# STM32F102 register map
File version: 1.1
CPU: CM3 r1p1, little endian, no MPU, no FPU, 4 interrupt priority bits
Registers are 32-bit, read-write, reset 0x0 unless marked. A register's access mark holds for its fields unless they carry their own. Offsets are from the block's base; [hi:lo] are bit positions; {n}, {i} and the like mark numbered series; 'fields as' and 'values as' point back to an identical list.

## PWR — Power control
Base 0x40007000
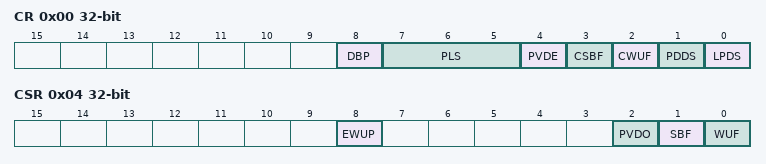
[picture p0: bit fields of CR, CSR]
0x00 CR — Power control register (PWR_CR)
  [8] DBP — Disable Backup Domain write protection
  [7:5] PLS — PVD Level Selection
  [4] PVDE — Power Voltage Detector Enable
  [3] CSBF — Clear STANDBY Flag
  [2] CWUF — Clear Wake-up Flag
  [1] PDDS — Power Down Deep Sleep
    0=STOP_MODE (Enter Stop mode when the CPU enters deepsleep); 1=STANDBY_MODE (Enter Standby mode when the CPU enters deepsleep)
  [0] LPDS — Low Power Deep Sleep
0x04 CSR access per field — Power control register (PWR_CR)
  [8] EWUP rw — Enable WKUP pin
  [2] PVDO ro — PVD Output
  [1] SBF ro — STANDBY Flag
  [0] WUF ro — Wake-Up Flag

## GPIOA — General purpose I/O
Base 0x40010800
Same registers: GPIOB 0x40010C00, GPIOC 0x40011000, GPIOD 0x40011400, GPIOE 0x40011800, GPIOF 0x40011C00, GPIOG 0x40012000
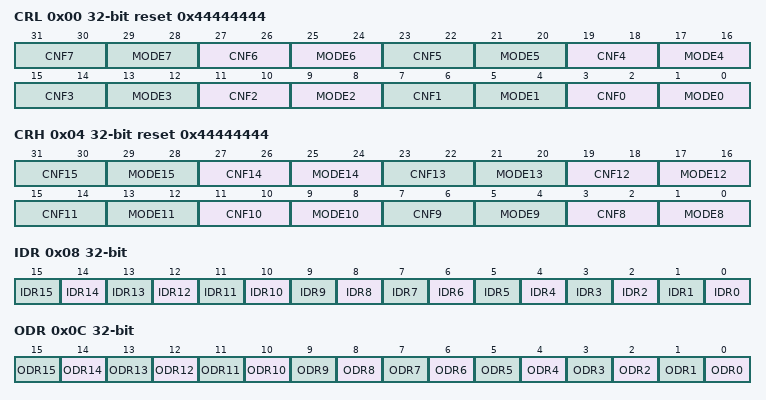
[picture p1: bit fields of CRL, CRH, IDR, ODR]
0x00 CRL reset 0x44444444 — Port configuration register low (GPIOn_CRL)
  [4n+3:4n+2] CNF{n} (n=0..7) — Port n.{n} configuration bits
    0=PushPull (Analog mode / Push-Pull mode); 1=OpenDrain (Floating input (reset state) / Open Drain-Mode); 2=AltPushPull (Input with pull-up/pull-down / Alternate Function Push-Pull Mode); 3=AltOpenDrain (Alternate Function Open-Drain Mode)
  [4n+1:4n] MODE{n} (n=0..7) — Port n.{n} mode bits
    0=Input mode (reset state); 1=Output mode 10 MHz; 2=Output2 (Output mode 2 MHz); 3=Output50 (Output mode 50 MHz)
0x04 CRH reset 0x44444444 — Port configuration register high (GPIOn_CRL)
  [4n-29:4n-30] CNF{n} (n=8..15) — Port n.{n} configuration bits
    values as CRL.CNF0
  [4n-31:4n-32] MODE{n} (n=8..15) — Port n.{n} mode bits
    values as CRL.MODE0
0x08 IDR ro — Port input data register (GPIOn_IDR)
  [n] IDR{n} (n=0..15) — Port input data
    0=Low (Input is logic low); 1=High (Input is logic high)
0x0C ODR — Port output data register (GPIOn_ODR)
  [n] ODR{n} (n=0..15) — Port output data
    0=Low (Set output to logic low); 1=High (Set output to logic high)
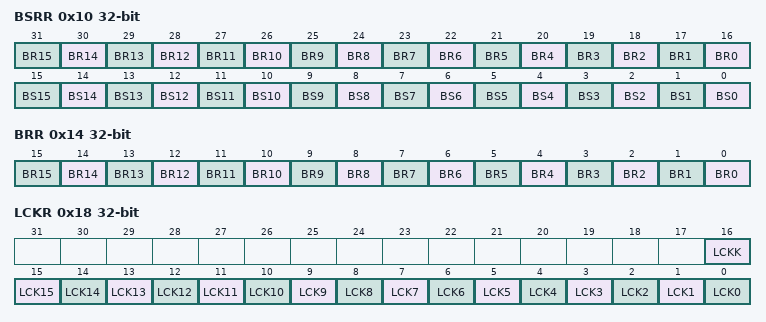
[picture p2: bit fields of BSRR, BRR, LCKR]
0x10 BSRR wo — Port bit set/reset register (GPIOn_BSRR)
  [n+16] BR{n} (n=0..15) — Reset bit {n}
    1=Resets the corresponding ODRx bit
  [n] BS{n} (n=0..15) — Set bit {n}
    1=Set (Sets the corresponding ODRx bit)
0x14 BRR wo — Port bit reset register (GPIOn_BRR)
  [n] BR{n} (n=0..15) — Reset bit {n}
    0=No action on the corresponding ODx bit; 1=Reset the ODx bit
0x18 LCKR — Port configuration lock register
  [16] LCKK — Lock key
    0=NotActive (Port configuration lock key not active); 1=Active (Port configuration lock key active)
  [n] LCK{n} (n=0..15) — Port A Lock bit {n}
    0=Unlocked (Port configuration not locked); 1=Locked (Port configuration locked)

## AFIO — Alternate function I/O
Base 0x40010000
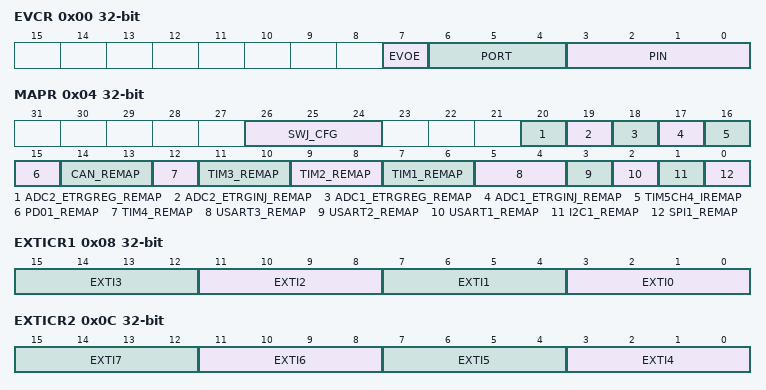
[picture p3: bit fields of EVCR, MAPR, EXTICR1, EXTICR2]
0x00 EVCR — Event Control Register (AFIO_EVCR)
  [7] EVOE — Event Output Enable
  [6:4] PORT — Port selection
  [3:0] PIN — Pin selection
0x04 MAPR access per field — AF remap and debug I/O configuration register (AFIO_MAPR)
  [26:24] SWJ_CFG wo — Serial wire JTAG configuration
  [20] ADC2_ETRGREG_REMAP rw — ADC 2 external trigger regular conversion remapping
  [19] ADC2_ETRGINJ_REMAP rw — ADC 2 external trigger injected conversion remapping
  [18] ADC1_ETRGREG_REMAP rw — ADC 1 external trigger regular conversion remapping
  [17] ADC1_ETRGINJ_REMAP rw — ADC 1 External trigger injected conversion remapping
  [16] TIM5CH4_IREMAP rw — Set and cleared by software
  [15] PD01_REMAP rw — Port D0/Port D1 mapping on OSCIN/OSCOUT
  [14:13] CAN_REMAP rw — CAN1 remapping
  [12] TIM4_REMAP rw — TIM4 remapping
  [11:10] TIM3_REMAP rw — TIM3 remapping
  [9:8] TIM2_REMAP rw — TIM2 remapping
  [7:6] TIM1_REMAP rw — TIM1 remapping
  [5:4] USART3_REMAP rw — USART3 remapping
  [3] USART2_REMAP rw — USART2 remapping
  [2] USART1_REMAP rw — USART1 remapping
  [1] I2C1_REMAP rw — I2C1 remapping
  [0] SPI1_REMAP rw — SPI1 remapping
0x08 EXTICR1 — External interrupt configuration register 1 (AFIO_EXTICR1)
  [all] fields
    0=PA (Select PAx as the source input for the EXTIx external interrupt); 1=PB (Select PBx as the source input for the EXTIx external interrupt); 2=PC (Select PCx as the source input for the EXTIx external interrupt); 3=PD (Select PDx as the source input for the EXTIx external interrupt); 4=PE (Select PEx as the source input for the EXTIx external interrupt); 5=PF (Select PFx as the source input for the EXTIx external interrupt); 6=PG (Select PGx as the source input for the EXTIx external interrupt)
  [4n+3:4n] EXTI{n} (n=0..3) — EXTI{n} configuration
0x0C EXTICR2 — External interrupt configuration register 2 (AFIO_EXTICR2)
  [all] fields
    values as the fields of EXTICR1
  [4n-13:4n-16] EXTI{n} (n=4..7) — EXTI{n} configuration
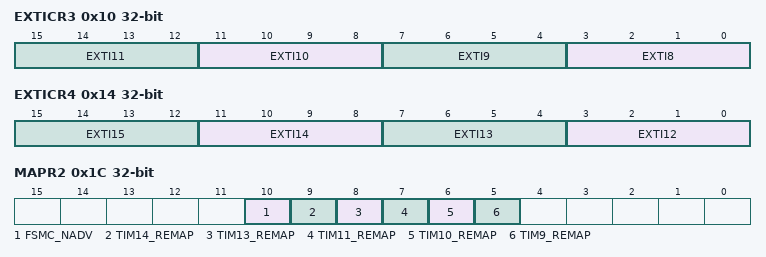
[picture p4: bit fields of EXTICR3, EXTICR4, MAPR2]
0x10 EXTICR3 — External interrupt configuration register 3 (AFIO_EXTICR3)
  [all] fields
    values as the fields of EXTICR1
  [4n-29:4n-32] EXTI{n} (n=8..11) — EXTI{n} configuration
0x14 EXTICR4 — External interrupt configuration register 4 (AFIO_EXTICR4)
  [all] fields
    values as the fields of EXTICR1
  [4n-45:4n-48] EXTI{n} (n=12..15) — EXTI{n} configuration
0x1C MAPR2 — AF remap and debug I/O configuration register
  [10] FSMC_NADV — NADV connect/disconnect
  [9] TIM14_REMAP — TIM14 remapping
  [8] TIM13_REMAP — TIM13 remapping
  [7] TIM11_REMAP — TIM11 remapping
  [6] TIM10_REMAP — TIM10 remapping
  [5] TIM9_REMAP — TIM9 remapping
